# RE01_256KB register map
Vendor: Renesas Electronics Corporation; Series: RE01; File version: 1.00.01
CPU: CM0PLUS r0p1, little endian, MPU, no FPU, VTOR, 2 interrupt priority bits, 32 interrupts
Registers are 8-bit, read-write, reset 0x0 unless marked. A register's access mark holds for its fields unless they carry their own. Offsets are from the block's base; [hi:lo] are bit positions; 'fields as' and 'values as' point back to an identical list.

## SCI2 — Serial Communication Interface 2
Base 0x40041240
Same registers: SCI3 0x40041260, SCI4 0x40041280, SCI5 0x400412A0, SCI9 0x40041320
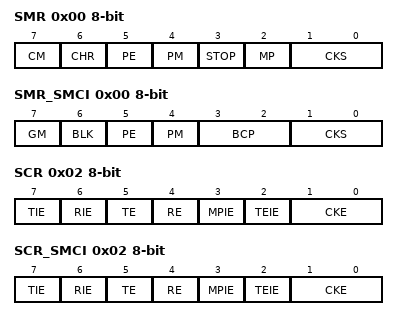
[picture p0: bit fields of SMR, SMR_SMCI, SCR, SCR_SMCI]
0x00 SMR — Serial Mode Register for Non-Smart Card Interface Mode (SCMR.SMIF = 0)
  [7] CM — Communication Mode
    0=Asynchronous mode or simple IIC mode; 1=Clock synchronous mode or simple SPI mode
  [6] CHR — Character Length
    0=SCMR.CHR1 = 0: Transmit/receive in 9-bit data length SCMR.CHR1 = 1: Transmit/receive in 8-bit data length (initial value); 1=SCMR.CHR1 = 0: Transmit/receive in 9-bit data length SCMR.CHR1 = 1: Transmit/receive in 7-bit data length
  [5] PE — Parity Enable
    0=When transmitting: Do not add parity bit When receiving: Do not check parity bit; 1=When transmitting: Add parity bit When receiving: Check parity bit
  [4] PM — Parity Mode
    0=Even parity; 1=Odd parity
  [3] STOP — Stop Bit Length
    0=1 stop bit; 1=2 stop bits
  [2] MP — Multi-Processor Mode
    0=Disable multi-processor communications function; 1=Enable multi-processor communications function
  [1:0] CKS — Clock Select
    0=PCLK clock (n = 0); 1=PCLK/4 clock (n = 1); 2=PCLK/16 clock (n = 2); 3=PCLK/64 clock (n = 3)
0x00 SMR_SMCI (alternate view of SMR) — Serial Mode Register for Smart Card Interface Mode (SCMR.SMIF = 1)
  [7] GM — GSM Mode
    0=Normal mode operation; 1=GSM mode operation
  [6] BLK — Block Transfer Mode
    0=Normal mode operation; 1=Block transfer mode operation
  [5] PE — Parity Enable
  [4] PM — Parity Mode
    0=Even parity; 1=Odd parity
  [3:2] BCP — Base Clock Pulse
  [1:0] CKS — Clock Select
    values as SMR.CKS
0x01 BRR reset 0xFF — Bit Rate Register
0x02 SCR — Serial Control Register for Non-Smart Card Interface Mode (SCMR.SMIF = 0)
  [7] TIE — Transmit Interrupt Enable
    0=Disable SCIn_TXI interrupt requests; 1=Enable SCIn_TXI interrupt requests
  [6] RIE — Receive Interrupt Enable
    0=Disable SCIn_RXI and SCIn_ERI interrupt requests; 1=Enable SCIn_RXI and SCIn_ERI interrupt requests
  [5] TE — Transmit Enable
    0=Disable serial transmission; 1=Enable serial transmission
  [4] RE — Receive Enable
    0=Disable serial reception; 1=Enable serial reception
  [3] MPIE — Multi-Processor Interrupt Enable
    0=Normal reception; 1=When data with the multi-processor bit set to 0 is received, the data is not read, and setting the status flags RDRF, ORER, and FER in SSR to 1 and the status flags SYER, PFER, and SBER in MESR are disabled. When data with the multi-processor bit set to 1 is received, the MPIE bit is automatically set to 0, and normal reception is resumed.
  [2] TEIE — Transmit End Interrupt Enable
    0=Disable SCIn_TEI interrupt requests; 1=Enable SCIn_TEI interrupt requests
  [1:0] CKE — Clock Enable
    0=In asynchronous mode, the SCKn pin is available for use as an I/O port based on the I/O port settings. In clock synchronous mode, the SCKn pin functions as the clock output pin.; 1=In asynchronous mode, a clock with the same frequency as the bit rate is output from the SCKn pin. In clock synchronous mode, the SCKn pin functions as the clock output pin.; other=Others (In asynchronous mode, input a clock with a frequency 16 times the bit rate from the SCKn pin when the SEMR.ABCS bit is 0. Input a clock signal with a frequency eight times the bit rate when the SEMR.ABCS bit is 1. In clock synchronous mode, the SCKn pin functions as the clock input pin.)
0x02 SCR_SMCI (alternate view of SCR) — Serial Control Register for Smart Card Interface Mode (SCMR.SMIF = 1)
  [7] TIE — Transmit Interrupt Enable
    values as SCR.TIE
  [6] RIE — Receive Interrupt Enable
    values as SCR.RIE
  [5] TE — Transmit Enable
    0=Disable serial transmission; 1=Enable serial transmission
  [4] RE — Receive Enable
    0=Disable serial reception; 1=Enable serial reception
  [3] MPIE — Multi-Processor Interrupt Enable
  [2] TEIE — Transmit End Interrupt Enable
  [1:0] CKE — Clock Enable
    0=When SMR_SMCI.GM = 0: Disable output The SCKn pin is available for use as an I/O port if set up in the I/O port settings When SMR_SMCI.GM = 1: Fix output low; 1=When SMR_SMCI.GM = 0: Output clock When SMR_SMCI.GM = 1: Output clock; 2=When SMR_SMCI.GM = 0: Setting prohibited When SMR_SMCI.GM = 1: Fix output high; 3=When SMR_SMCI.GM = 0: Setting prohibited When SMR_SMCI.GM = 1: Output clock
0x03 TDR reset 0xFF — Transmit Data Register
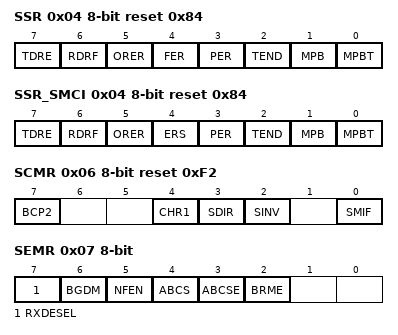
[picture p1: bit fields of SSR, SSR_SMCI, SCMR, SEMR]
0x04 SSR reset 0x84 — Serial Status Register for Non-Smart Card Interface and Non-FIFO Mode (SCMR.SMIF = 0, FCR.FM = 0)
  [7] TDRE — Transmit Data Empty Flag
    0=Transmit data in TDR register; 1=No transmit data in TDR register
  [6] RDRF — Receive Data Full Flag
    0=No received data in RDR register; 1=Received data in RDR register
  [5] ORER — Overrun Error Flag
    0=No overrun error occurred; 1=Overrun error occurred
  [4] FER — Framing Error Flag
    0=No framing error occurred; 1=Framing error occurred
  [3] PER — Parity Error Flag
    0=No parity error occurred; 1=Parity error occurred
  [2] TEND ro — Transmit End Flag
    0=A character is being transmitted; 1=Character transfer is complete
  [1] MPB ro — Multi-Processor
    0=Data transmission cycle; 1=ID transmission cycle
  [0] MPBT — Multi-Processor Bit Transfer
    0=Data transmission cycle; 1=ID transmission cycle
0x04 SSR_SMCI reset 0x84 (alternate view of SSR) — Serial Status Register for Smart Card Interface Mode (SCMR.SMIF = 1)
  [7] TDRE — Transmit Data Empty Flag
    values as SSR.TDRE
  [6] RDRF — Receive Data Full Flag
    values as SSR.RDRF
  [5] ORER — Overrun Error Flag
    0=No overrun error occurred; 1=Overrun error occurred
  [4] ERS — Error Signal Status Flag
    0=No low error signal response; 1=Low error signal response occurred
  [3] PER — Parity Error Flag
    0=No parity error occurred; 1=Parity error occurred
  [2] TEND ro — Transmit End Flag
    values as SSR.TEND
  [1] MPB ro — Multi-Processor
  [0] MPBT — Multi-Processor Bit Transfer
0x05 RDR ro — Receive Data Register
0x06 SCMR reset 0xF2 — Smart Card Mode Register
  [7] BCP2 — Base Clock Pulse 2
  [4] CHR1 — Character Length 1
    0=SMR.CHR = 0: Transmit/receive in 9-bit data length SMR.CHR = 1: Transmit/receive in 9-bit data length; 1=SMR.CHR = 0: Transmit/receive in 8-bit data length (initial value) SMR.CHR = 1: Transmit/receive in 7-bit data length
  [3] SDIR — Transmitted/Received Data Transfer Direction
    0=Transfer LSB-first; 1=Transfer MSB-first
  [2] SINV — Transmitted/Received Data Invert
    0=TDR contents are transmitted as they are. Received data is stored as received in the RDR register.; 1=TDR register contents are inverted before transmission. Receive data is stored in inverted form in the RDR register.
  [0] SMIF — Smart Card Interface Mode Select
    0=Non-smart card interface mode (asynchronous mode, clock synchronous mode, simple SPI mode, or simple IIC mode); 1=Smart card interface mode
0x07 SEMR — Serial Extended Mode Register
  [7] RXDESEL — Asynchronous Start Bit Edge Detection Select
    0=Detect low level on RXDn pin as start bit; 1=Detect falling edge of RXDn pin as start bit
  [6] BGDM — Baud Rate Generator Double-Speed Mode Select
    0=Output clock from baud rate generator with normal frequency; 1=Output clock from baud rate generator with doubled frequency
  [5] NFEN — Digital Noise Filter Function Enable
    0=In asynchronous mode: Disable noise cancellation function for RXDn input signal In simple IIC mode: Disable noise cancellation function for SSCLn and SSDAn input signals; 1=In asynchronous mode: Enable noise cancellation function for RXDn input signal In simple IIC mode: Enable noise cancellation function for SSCLn and SSDAn input signals
  [4] ABCS — Basic Clock Selection
  [3] ABCSE — Asynchronous Mode Extended Base Clock Select 1
    0=Clock cycles for 1-bit period determined by combination of the BGDM and ABCS bits in the SEMR register; 1=Baud rate is 6 base clock cycles for 1-bit period
  [2] BRME — Bit Rate Modulation Enable
    0=Disable bit rate modulation function; 1=Enable bit rate modulation function
0x08 SNFR — Noise Filter Setting Register
  [2:0] NFCS — Noise Filter Clock Select
    0=In asynchronous mode: Use clock signal divided by 1 with noise filter In simple IIC mode: Setting prohibited; 1=In asynchronous mode: Setting prohibited In simple IIC mode: Use clock signal divided by 1 with noise filter; 2=In asynchronous mode: Setting prohibited In simple IIC mode: Use clock signal divided by 2 with noise filter; 3=In asynchronous mode: Setting prohibited In simple IIC mode: Use clock signal divided by 4 with noise filter; 4=In asynchronous mode: Setting prohibited In simple IIC mode: Use clock signal divided by 8 with noise filter; other=Others (Setting prohibited)
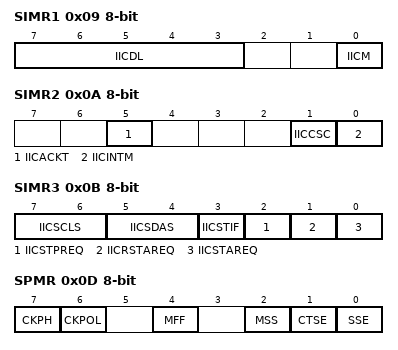
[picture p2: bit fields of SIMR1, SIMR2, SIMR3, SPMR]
0x09 SIMR1 — IIC Mode Register 1
  [7:3] IICDL — SSDAn Delay Output Select
    0=No output delay; other=Others ((IICDL - 1) to (IICDL) cycles)
  [0] IICM — Simple IIC Mode Select
    0=SCMR.SMIF = 0: Asynchronous mode (including multi-processor mode), clock synchronous mode, or simple SPI mode SCMR.SMIF = 1: Smart card interface mode; 1=SCMR.SMIF = 0: Simple IIC mode SCMR.SMIF = 1: Setting prohibited
0x0A SIMR2 — IIC Mode Register 2
  [5] IICACKT — ACK Transmission Data
    0=ACK transmission; 1=NACK transmission and ACK/NACK reception
  [1] IICCSC — Clock Synchronization
    0=Do not synchronize with clock signal; 1=Synchronize with clock signal
  [0] IICINTM — IIC Interrupt Mode Select
    0=Use ACK/NACK interrupts; 1=Use reception and transmission interrupts
0x0B SIMR3 — IIC Mode Register 3
  [7:6] IICSCLS — SSCLn Output Select
    0=Output serial clock; 1=Generate start, restart, or stop condition; 2=Output low on SSCLn pin; 3=Drive SSCLn pin to high-impedance state
  [5:4] IICSDAS — SSDAn Output Select
    0=Output serial data; 1=Generate start, restart, or stop condition; 2=Output low on SSDAn pin; 3=Drive SSDAn pin to high-impedance state
  [3] IICSTIF — Issuing of Start, Restart, or Stop Condition Completed Flag
    0=No requests are being made for generating conditions, or a condition is being generated; 1=Generation of start, restart, or stop condition is complete. When 0 is written to IICSTIF, it is set to 0
  [2] IICSTPREQ — Stop Condition Generation
    0=Do not generate stop condition; 1=Generate stop condition
  [1] IICRSTAREQ — Restart Condition Generation
    0=Do not generate restart condition; 1=Generate restart condition
  [0] IICSTAREQ — Start Condition Generation
    0=Do not generate start condition; 1=Generate start condition
0x0C SISR ro — IIC Status Register
  [0] IICACKR — ACK Reception Data Flag
    0=ACK received; 1=NACK received
0x0D SPMR — SPI Mode Register
  [7] CKPH — Clock Phase Select
    0=Do not delay clock; 1=Delay clock
  [6] CKPOL — Clock Polarity Select
    0=Do not invert clock polarity; 1=Invert clock polarity
  [4] MFF — Mode Fault Flag
    0=No mode fault error; 1=Mode fault error
  [2] MSS — Master Slave Select
    0=Transmit through TXDn pin and receive through RXDn pin (master mode); 1=Receive through TXDn pin and transmit through RXDn pin (slave mode)
  [1] CTSE — CTS Enable
    0=Disable CTS function (enable RTS output function); 1=Enable CTS function
  [0] SSE — SSn Pin Function Enable
    0=Disable SSn pin function; 1=Enable SSn pin function
0x0E TDRHL 16-bit reset 0xFFFF (alternate view of FTDRHL) — Transmit Data Register
  [8:0] TDAT — Serial Transmit Data
0x10 RDRHL 16-bit ro (alternate view of FRDRHL) — Receive Data Register
  [8:0] RDAT — Serial Receive Data
0x12 MDDR reset 0xFF — Modulation Duty Register
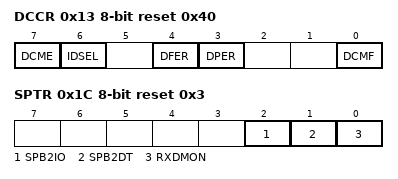
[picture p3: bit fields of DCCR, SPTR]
0x13 DCCR reset 0x40 — Data Compare Match Control Register
  [7] DCME — Data Compare Match Enable
    0=Disable address match function; 1=Enable address match function
  [6] IDSEL — ID Frame Select
    0=Always compare data regardless of the MPB bit value; 1=Only compare data when MPB bit = 1 (ID frame)
  [4] DFER — Data Compare Match Framing Error Flag
    0=No framing error occurred; 1=Framing error occurred
  [3] DPER — Data Compare Match Parity Error Flag
    0=No parity error occurred; 1=Parity error occurred
  [0] DCMF — Data Compare Match Flag
    0=Not matched; 1=Matched
0x1A CDR 16-bit — Compare Match Data Register
  [8:0] CMPD — Compare Match Data
0x1C SPTR reset 0x3 — Serial Port Register
  [2] SPB2IO — Serial Port Break I/O
    0=Do not output value of SPB2DT bit on TXD pin; 1=Output value of SPB2DT bit on TXD pin
  [1] SPB2DT — Serial Port Break Data Select
  [0] RXDMON ro — Serial Input Data Monitor
